# APM32F403 register map
File version: 1.0
CPU: CM4 r1p0, little endian, no MPU, no FPU, 4 interrupt priority bits
Registers are 32-bit, read-write, reset 0x0 unless marked. A register's access mark holds for its fields unless they carry their own. Offsets are from the block's base; [hi:lo] are bit positions; {n}, {i} and the like mark numbered series.

## RCM — Reset and clock control
Base 0x40021000
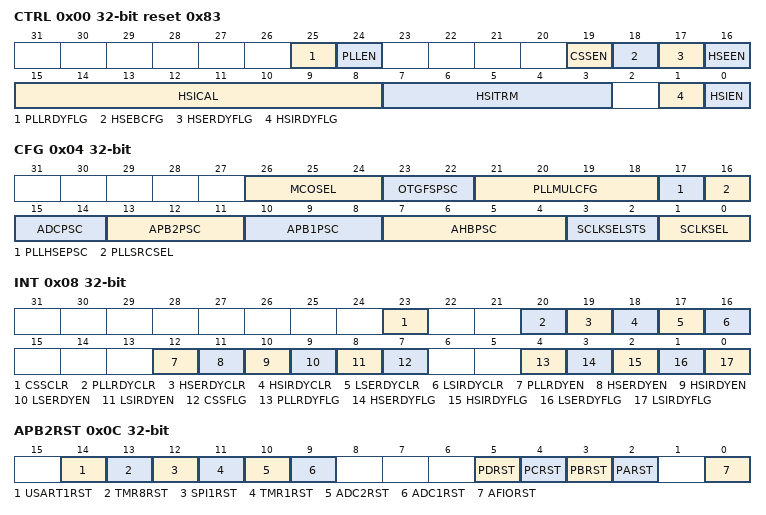
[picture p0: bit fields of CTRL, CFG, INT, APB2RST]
0x00 CTRL access per field reset 0x83 — Clock control register
  [25] PLLRDYFLG ro — PLL clock ready flag
  [24] PLLEN rw — PLL enable
  [19] CSSEN rw — Clock Security System enable
  [18] HSEBCFG rw — External High Speed clock Bypass
  [17] HSERDYFLG ro — External High Speed clock ready flag
  [16] HSEEN rw — External High Speed clock enable
  [15:8] HSICAL ro — Internal High Speed clock Calibration
  [7:3] HSITRM rw — Internal High Speed clock trimming
  [1] HSIRDYFLG ro — Internal High Speed clock ready flag
  [0] HSIEN rw — Internal High Speed clock enable
0x04 CFG access per field — Clock configuration register
  [26:24] MCOSEL rw — Main Clock Output Select
  [23:22] OTGFSPSC rw — OTGFS Prescaler Factor
  [21:18] PLLMULCFG rw — PLL Multiplication Factor
  [17] PLLHSEPSC rw — HSE divider for PLL entry
  [16] PLLSRCSEL rw — PLL entry clock source
  [15:14] ADCPSC rw — ADC prescaler
  [13:11] APB2PSC rw — APB High speed prescaler
  [10:8] APB1PSC rw — APB Low speed prescaler
  [7:4] AHBPSC rw — AHB prescaler
  [3:2] SCLKSELSTS ro — System Clock Switch Status
  [1:0] SCLKSEL rw — System clock Switch
0x08 INT access per field — Clock interrupt control register
  [23] CSSCLR wo — Clock security system interrupt clear
  [20] PLLRDYCLR wo — PLL Ready Interrupt Clear
  [19] HSERDYCLR wo — HSE Ready Interrupt Clear
  [18] HSIRDYCLR wo — HSI Ready Interrupt Clear
  [17] LSERDYCLR wo — LSE Ready Interrupt Clear
  [16] LSIRDYCLR wo — LSI Ready Interrupt Clear
  [12] PLLRDYEN rw — PLL Ready Interrupt Enable
  [11] HSERDYEN rw — HSE Ready Interrupt Enable
  [10] HSIRDYEN rw — HSI Ready Interrupt Enable
  [9] LSERDYEN rw — LSE Ready Interrupt Enable
  [8] LSIRDYEN rw — LSI Ready Interrupt Enable
  [7] CSSFLG ro — Clock Security System Interrupt flag
  [4] PLLRDYFLG ro — PLL Ready Interrupt flag
  [3] HSERDYFLG ro — HSE Ready Interrupt flag
  [2] HSIRDYFLG ro — HSI Ready Interrupt flag
  [1] LSERDYFLG ro — LSE Ready Interrupt flag
  [0] LSIRDYFLG ro — LSI Ready Interrupt flag
0x0C APB2RST — APB2 peripheral reset register
  [14] USART1RST — USART1 reset
  [13] TMR8RST — TMR8 timer reset
  [12] SPI1RST — SPI 1 reset
  [11] TMR1RST — TMR1 timer reset
  [10] ADC2RST — ADC 2 interface reset
  [9] ADC1RST — ADC 1 interface reset
  [5] PDRST — IO port D reset
  [4] PCRST — IO port C reset
  [3] PBRST — IO port B reset
  [2] PARST — IO port A reset
  [0] AFIORST — Alternate function I/O reset
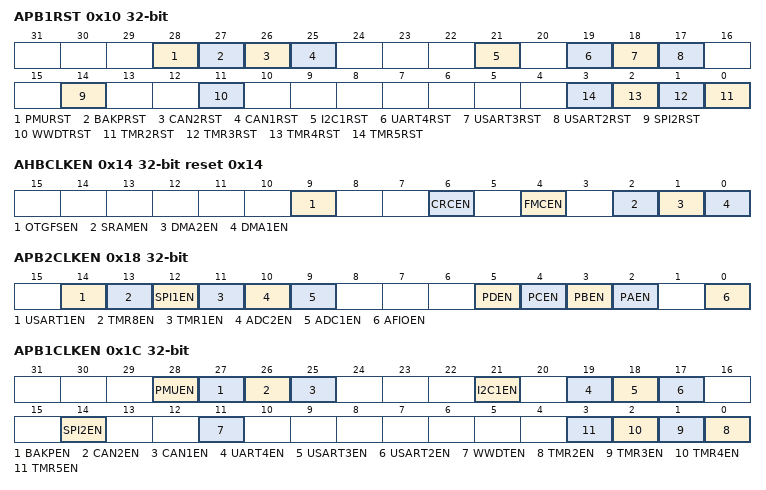
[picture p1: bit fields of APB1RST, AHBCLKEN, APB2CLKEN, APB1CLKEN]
0x10 APB1RST — APB1 peripheral reset register
  [28] PMURST — Power interface reset
  [27] BAKPRST — Bakr interface reset
  [26] CAN2RST — CAN2 reset
  [25] CAN1RST — CAN1 reset
  [21] I2C1RST — I2C1 reset
  [19] UART4RST — UART 4 reset
  [18] USART3RST — USART 3 reset
  [17] USART2RST — USART 2 reset
  [14] SPI2RST — SPI2 reset
  [11] WWDTRST — Window watchdog reset
  [n-2] TMR{n}RST (n=2..5) — Timer {n} reset
0x14 AHBCLKEN reset 0x14 — AHB clock enable register
  [9] OTGFSEN — OTG_FS clock enable
  [6] CRCEN — CRC clock enable
  [4] FMCEN — FMC clock enable
  [2] SRAMEN — SRAM interface clock enable
  [1] DMA2EN — DMA2 clock enable
  [0] DMA1EN — DMA1 clock enable
0x18 APB2CLKEN — APB2 clock enable register
  [14] USART1EN — USART1 clock enable
  [13] TMR8EN — TMR8 Timer clock enable
  [12] SPI1EN — SPI 1 clock enable
  [11] TMR1EN — TMR1 Timer clock enable
  [10] ADC2EN — ADC 2 interface clock enable
  [9] ADC1EN — ADC 1 interface clock enable
  [5] PDEN — I/O port D clock enable
  [4] PCEN — I/O port C clock enable
  [3] PBEN — I/O port B clock enable
  [2] PAEN — I/O port A clock enable
  [0] AFIOEN — Alternate function I/O clock enable
0x1C APB1CLKEN — APB1 clock enable register
  [28] PMUEN — Power interface clock enable
  [27] BAKPEN — Bakr interface clock enable
  [26] CAN2EN — CAN2 clock enable
  [25] CAN1EN — CAN1 clock enable
  [21] I2C1EN — I2C 1 clock enable
  [19] UART4EN — UART 4 clock enable
  [18] USART3EN — USART 3 clock enable
  [17] USART2EN — USART 2 clock enable
  [14] SPI2EN — SPI 2 clock enable
  [11] WWDTEN — Window watchdog clock enable
  [n-2] TMR{n}EN (n=2..5) — Timer {n} clock enable
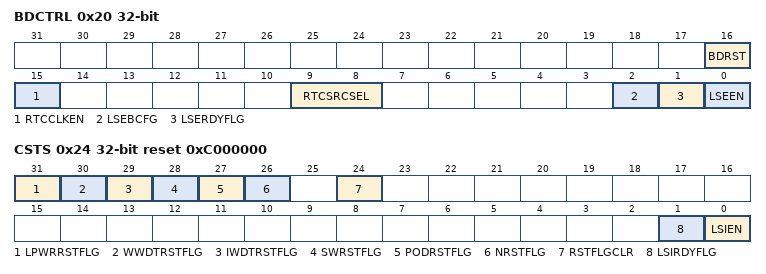
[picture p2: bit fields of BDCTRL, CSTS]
0x20 BDCTRL access per field — Bakr domain control register
  [16] BDRST rw — Bakr domain software reset
  [15] RTCCLKEN rw — RTC clock enable
  [9:8] RTCSRCSEL rw — RTC clock source selection
  [2] LSEBCFG rw — External Low Speed oscillator bypass
  [1] LSERDYFLG ro — External Low Speed oscillator ready
  [0] LSEEN rw — External Low Speed oscillator enable
0x24 CSTS access per field reset 0xC000000 — Control/status register
  [31] LPWRRSTFLG rw — Low-power reset flag
  [30] WWDTRSTFLG rw — Window watchdog reset flag
  [29] IWDTRSTFLG rw — Independent watchdog reset flag
  [28] SWRSTFLG rw — Software reset flag
  [27] PODRSTFLG rw — POR/PDR reset flag
  [26] NRSTFLG rw — PIN reset flag
  [24] RSTFLGCLR rw — Remove reset flag
  [1] LSIRDYFLG ro — Internal low speed oscillator ready
  [0] LSIEN rw — Internal low speed oscillator enable
0x28 AHBRST — AHB1 peripheral reset register
  [9] OTGFSRST — OTG_FS Reset
